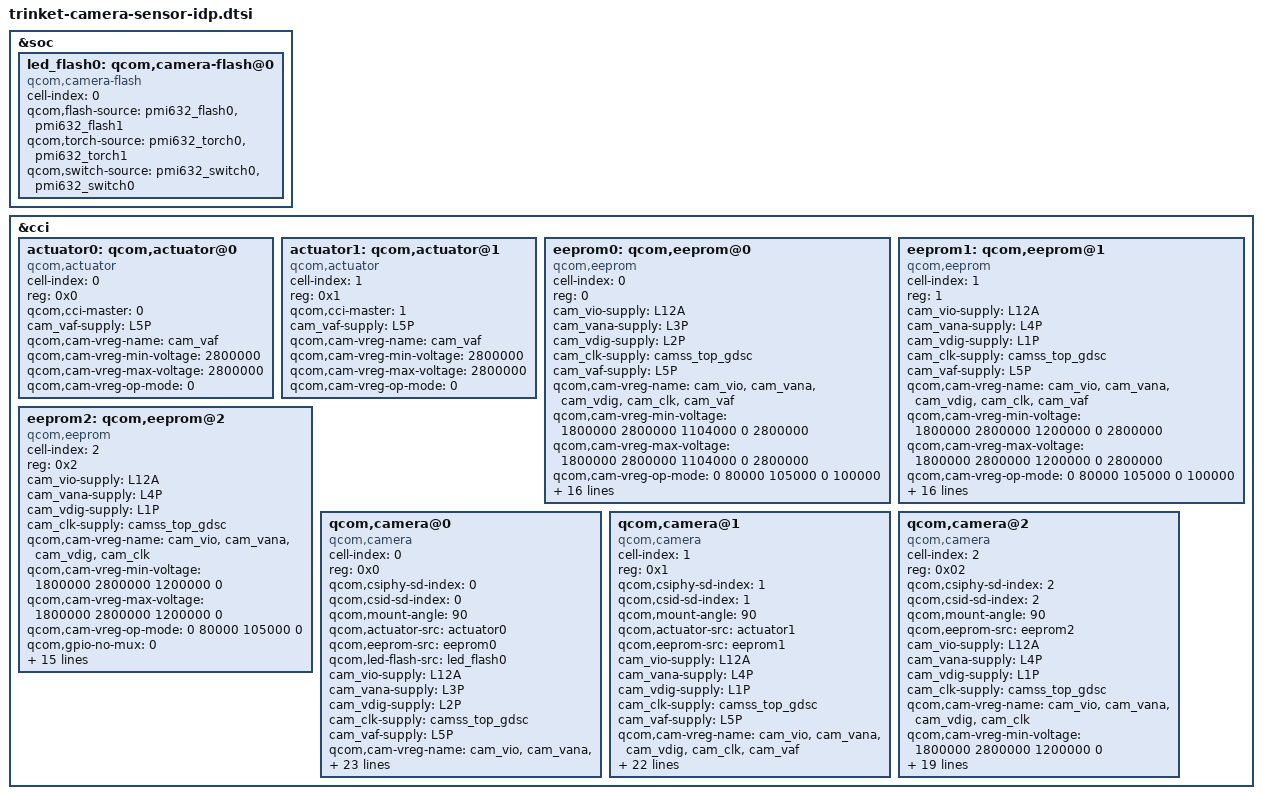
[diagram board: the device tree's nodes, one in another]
/*
 * Copyright (c) 2019, The Linux Foundation. All rights reserved.
 *
 * This program is free software; you can redistribute it and/or modify
 * it under the terms of the GNU General Public License version 2 and
 * only version 2 as published by the Free Software Foundation.
 *
 * This program is distributed in the hope that it will be useful,
 * but WITHOUT ANY WARRANTY; without even the implied warranty of
 * MERCHANTABILITY or FITNESS FOR A PARTICULAR PURPOSE.  See the
 * GNU General Public License for more details.
 */
&soc {
	led_flash0: qcom,camera-flash@0 {
		cell-index = <0>;
		compatible = "qcom,camera-flash";
		qcom,flash-source = <&pmi632_flash0 &pmi632_flash1>;
		qcom,torch-source = <&pmi632_torch0 &pmi632_torch1>;
		qcom,switch-source = <&pmi632_switch0 &pmi632_switch0>;
		status = "ok";
	};
};

&cci {
	actuator0: qcom,actuator@0 {
		cell-index = <0>;
		reg = <0x0>;
		compatible = "qcom,actuator";
		qcom,cci-master = <0>;
		cam_vaf-supply = <&L5P>;
		qcom,cam-vreg-name = "cam_vaf";
		qcom,cam-vreg-min-voltage = <2800000>;
		qcom,cam-vreg-max-voltage = <2800000>;
		qcom,cam-vreg-op-mode = <0>;
	};

	actuator1: qcom,actuator@1 {
		cell-index = <1>;
		reg = <0x1>;
		compatible = "qcom,actuator";
		qcom,cci-master = <1>;
		cam_vaf-supply = <&L5P>;
		qcom,cam-vreg-name = "cam_vaf";
		qcom,cam-vreg-min-voltage = <2800000>;
		qcom,cam-vreg-max-voltage = <2800000>;
		qcom,cam-vreg-op-mode = <0>;
	};

	eeprom0: qcom,eeprom@0 {
		cell-index = <0>;
		reg = <0>;
		compatible = "qcom,eeprom";
		cam_vio-supply = <&L12A>;
		cam_vana-supply = <&L3P>;
		cam_vdig-supply = <&L2P>;
		cam_clk-supply = <&camss_top_gdsc>;
		cam_vaf-supply = <&L5P>;
		qcom,cam-vreg-name = "cam_vio", "cam_vana", "cam_vdig",
				"cam_clk", "cam_vaf";
		qcom,cam-vreg-min-voltage = <1800000 2800000 1104000 0 2800000>;
		qcom,cam-vreg-max-voltage = <1800000 2800000 1104000 0 2800000>;
		qcom,cam-vreg-op-mode = <0 80000 105000 0 100000>;
		qcom,gpio-no-mux = <0>;
		pinctrl-names = "cam_default", "cam_suspend";
		pinctrl-0 = <&cam_sensor_mclk0_active
				&cam_sensor_rear_active>;
		pinctrl-1 = <&cam_sensor_mclk0_suspend
				&cam_sensor_rear_suspend>;
		gpios = <&tlmm 34 0>,
			<&tlmm 48 0>;
		qcom,gpio-reset = <1>;
		qcom,gpio-req-tbl-num = <0 1>;
		qcom,gpio-req-tbl-flags = <1 0>;
		qcom,gpio-req-tbl-label = "CAMIF_MCLK0",
					"CAM_RESET0";
		qcom,sensor-position = <0>;
		qcom,cci-master = <0>;
		status = "ok";
		clocks = <&clock_gcc GCC_CAMSS_MCLK0_CLK_SRC>,
				<&clock_gcc GCC_CAMSS_MCLK0_CLK>;
		clock-names = "cam_src_clk", "cam_clk";
		qcom,clock-rates = <24000000 0>;
	};

	eeprom1: qcom,eeprom@1 {
		cell-index = <1>;
		reg = <1>;
		compatible = "qcom,eeprom";
		cam_vio-supply = <&L12A>;
		cam_vana-supply = <&L4P>;
		cam_vdig-supply = <&L1P>;
		cam_clk-supply = <&camss_top_gdsc>;
		cam_vaf-supply = <&L5P>;
		qcom,cam-vreg-name = "cam_vio", "cam_vana", "cam_vdig",
				"cam_clk", "cam_vaf";
		qcom,cam-vreg-min-voltage = <1800000 2800000 1200000 0 2800000>;
		qcom,cam-vreg-max-voltage = <1800000 2800000 1200000 0 2800000>;
		qcom,cam-vreg-op-mode = <0 80000 105000 0 100000>;
		qcom,gpio-no-mux = <0>;
		pinctrl-names = "cam_default", "cam_suspend";
		pinctrl-0 = <&cam_sensor_mclk1_active
				 &cam_sensor_rear2_active>;
		pinctrl-1 = <&cam_sensor_mclk1_suspend
				 &cam_sensor_rear2_suspend>;
		gpios = <&tlmm 35 0>,
			<&tlmm 46 0>;
		qcom,gpio-reset = <1>;
		qcom,gpio-req-tbl-num = <0 1>;
		qcom,gpio-req-tbl-flags = <1 0>;
		qcom,gpio-req-tbl-label = "CAMIF_MCLK1",
					  "CAM_RESET1";
		qcom,sensor-position = <0>;
		qcom,cci-master = <1>;
		status = "ok";
		clocks = <&clock_gcc GCC_CAMSS_MCLK1_CLK_SRC>,
			<&clock_gcc GCC_CAMSS_MCLK1_CLK>;
		clock-names = "cam_src_clk", "cam_clk";
		qcom,clock-rates = <24000000 0>;
	};

	eeprom2: qcom,eeprom@2 {
		cell-index = <2>;
		reg = <0x2>;
		compatible = "qcom,eeprom";
		cam_vio-supply = <&L12A>;
		cam_vana-supply = <&L4P>;
		cam_vdig-supply = <&L1P>;
		cam_clk-supply = <&camss_top_gdsc>;
		qcom,cam-vreg-name = "cam_vio", "cam_vana", "cam_vdig",
				"cam_clk";
		qcom,cam-vreg-min-voltage = <1800000 2800000 1200000 0>;
		qcom,cam-vreg-max-voltage = <1800000 2800000 1200000 0>;
		qcom,cam-vreg-op-mode = <0 80000 105000 0>;
		qcom,gpio-no-mux = <0>;
		pinctrl-names = "cam_default", "cam_suspend";
		pinctrl-0 = <&cam_sensor_mclk2_active
			&cam_sensor_front_active>;
		pinctrl-1 = <&cam_sensor_mclk2_suspend
			&cam_sensor_front_suspend>;
		gpios = <&tlmm 36 0>,
		    <&tlmm 42 0>;
		qcom,gpio-reset = <1>;
		qcom,gpio-req-tbl-num = <0 1>;
		qcom,gpio-req-tbl-flags = <1 0>;
		qcom,gpio-req-tbl-label = "CAMIF_MCLK",
				"CAM_RESET";
		qcom,sensor-position = <0>;
		qcom,sensor-mode = <0>;
		qcom,cci-master = <1>;
		status = "ok";
		clocks = <&clock_gcc GCC_CAMSS_MCLK2_CLK_SRC>,
		    <&clock_gcc GCC_CAMSS_MCLK2_CLK>;
		clock-names = "cam_src_clk", "cam_clk";
		qcom,clock-rates = <24000000 0>;
	};

	qcom,camera@0 {
		cell-index = <0>;
		compatible = "qcom,camera";
		reg = <0x0>;
		qcom,csiphy-sd-index = <0>;
		qcom,csid-sd-index = <0>;
		qcom,mount-angle = <90>;
		qcom,actuator-src = <&actuator0>;
		qcom,eeprom-src = <&eeprom0>;
		qcom,led-flash-src = <&led_flash0>;
		cam_vio-supply = <&L12A>;
		cam_vana-supply = <&L3P>;
		cam_vdig-supply = <&L2P>;
		cam_clk-supply = <&camss_top_gdsc>;
		cam_vaf-supply = <&L5P>;
		qcom,cam-vreg-name = "cam_vio", "cam_vana", "cam_vdig",
				"cam_clk", "cam_vaf";
		qcom,cam-vreg-min-voltage = <1800000 2800000 1104000 0 2800000>;
		qcom,cam-vreg-max-voltage = <1800000 2800000 1104000 0 2800000>;
		qcom,cam-vreg-op-mode = <0 80000 105000 0 100000>;
		qcom,gpio-no-mux = <0>;
		pinctrl-names = "cam_default", "cam_suspend";
		pinctrl-0 = <&cam_sensor_mclk0_active
				&cam_sensor_rear_active>;
		pinctrl-1 = <&cam_sensor_mclk0_suspend
				&cam_sensor_rear_suspend>;
		gpios = <&tlmm 34 0>,
			<&tlmm 48 0>;
		qcom,gpio-reset = <1>;
		qcom,gpio-req-tbl-num = <0 1>;
		qcom,gpio-req-tbl-flags = <1 0>;
		qcom,gpio-req-tbl-label = "CAMIF_MCLK0",
					"CAM_RESET0";
		qcom,sensor-position = <0>;
		qcom,sensor-mode = <0>;
		qcom,cci-master = <0>;
		status = "ok";
		clocks = <&clock_gcc GCC_CAMSS_MCLK0_CLK_SRC>,
				<&clock_gcc GCC_CAMSS_MCLK0_CLK>;
		clock-names = "cam_src_clk", "cam_clk";
		qcom,clock-rates = <24000000 0>;
	};

	qcom,camera@1 {
		cell-index = <1>;
		compatible = "qcom,camera";
		reg = <0x1>;
		qcom,csiphy-sd-index = <1>;
		qcom,csid-sd-index = <1>;
		qcom,mount-angle = <90>;
		qcom,actuator-src = <&actuator1>;
		qcom,eeprom-src = <&eeprom1>;
		cam_vio-supply = <&L12A>;
		cam_vana-supply = <&L4P>;
		cam_vdig-supply = <&L1P>;
		cam_clk-supply = <&camss_top_gdsc>;
		cam_vaf-supply = <&L5P>;
		qcom,cam-vreg-name = "cam_vio", "cam_vana", "cam_vdig",
				"cam_clk", "cam_vaf";
		qcom,cam-vreg-min-voltage = <1800000 2800000 1200000 0 2800000>;
		qcom,cam-vreg-max-voltage = <1800000 2800000 1200000 0 2800000>;
		qcom,cam-vreg-op-mode = <0 80000 105000 0 100000>;
		qcom,gpio-no-mux = <0>;
		pinctrl-names = "cam_default", "cam_suspend";
		pinctrl-0 = <&cam_sensor_mclk1_active
				 &cam_sensor_rear2_active>;
		pinctrl-1 = <&cam_sensor_mclk1_suspend
				 &cam_sensor_rear2_suspend>;
		gpios = <&tlmm 35 0>,
			<&tlmm 46 0>;
		qcom,gpio-reset = <1>;
		qcom,gpio-req-tbl-num = <0 1>;
		qcom,gpio-req-tbl-flags = <1 0>;
		qcom,gpio-req-tbl-label = "CAMIF_MCLK1",
					  "CAM_RESET1";
		qcom,sensor-position = <0>;
		qcom,sensor-mode = <0>;
		qcom,cci-master = <1>;
		status = "ok";
		clocks = <&clock_gcc GCC_CAMSS_MCLK1_CLK_SRC>,
			<&clock_gcc GCC_CAMSS_MCLK1_CLK>;
		clock-names = "cam_src_clk", "cam_clk";
		qcom,clock-rates = <24000000 0>;
	};

	qcom,camera@2 {
		cell-index = <2>;
		compatible = "qcom,camera";
		reg = <0x02>;
		qcom,csiphy-sd-index = <2>;
		qcom,csid-sd-index = <2>;
		qcom,mount-angle = <90>;
		qcom,eeprom-src = <&eeprom2>;
		cam_vio-supply = <&L12A>;
		cam_vana-supply = <&L4P>;
		cam_vdig-supply = <&L1P>;
		cam_clk-supply = <&camss_top_gdsc>;
		qcom,cam-vreg-name = "cam_vio", "cam_vana", "cam_vdig",
				"cam_clk";
		qcom,cam-vreg-min-voltage = <1800000 2800000 1200000 0>;
		qcom,cam-vreg-max-voltage = <1800000 2800000 1200000 0>;
		qcom,cam-vreg-op-mode = <0 80000 105000 0>;
		qcom,gpio-no-mux = <0>;
		pinctrl-names = "cam_default", "cam_suspend";
		pinctrl-0 = <&cam_sensor_mclk2_active
				 &cam_sensor_front_active>;
		pinctrl-1 = <&cam_sensor_mclk2_suspend
				 &cam_sensor_front_suspend>;
		gpios = <&tlmm 36 0>,
			<&tlmm 42 0>;
		qcom,gpio-reset = <1>;
		qcom,gpio-req-tbl-num = <0 1>;
		qcom,gpio-req-tbl-flags = <1 0>;
		qcom,gpio-req-tbl-label = "CAMIF_MCLK2",
					"CAM_RESET2";
		qcom,sensor-mode = <0>;
		qcom,cci-master = <1>;
		status = "ok";
		clocks = <&clock_gcc GCC_CAMSS_MCLK2_CLK_SRC>,
			<&clock_gcc GCC_CAMSS_MCLK2_CLK>;
		clock-names = "cam_src_clk", "cam_clk";
		qcom,clock-rates = <24000000 0>;
	};

};
